# B6x register map
Vendor: XiaoMan; Series: B6 SOC; File version: 20260307
CPU: CM0+ r0p0, little endian, no MPU, no FPU, 2 interrupt priority bits
Registers are 32-bit, read-write, reset 0x0 unless marked. A register's access mark holds for its fields unless they carry their own. Offsets are from the block's base; [hi:lo] are bit positions; {n}, {i} and the like mark numbered series.

## SPIM — SPI Master
Base 0x40004000
0x00 RX_DATA
0x04 TX_DATA
0x08 TXRX_BGN
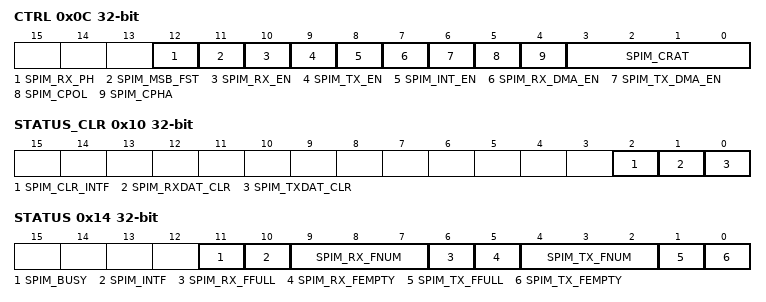
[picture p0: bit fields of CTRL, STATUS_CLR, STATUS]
0x0C CTRL
  [12] SPIM_RX_PH — 1: delay one phase to sample the miso
  [11] SPIM_MSB_FST — 1: MSB first, 0: LSB first
  [10] SPIM_RX_EN — receive from SPI slave enable
  [9] SPIM_TX_EN — transmit to SPI slave enable
  [8] SPIM_INT_EN — interrupt enable bit
  [7] SPIM_RX_DMA_EN — 0: RX work as mcu mode
  [6] SPIM_TX_DMA_EN — 0: TX work as mcu mode
  [5] SPIM_CPOL — clock polarity bit, 0: sck is low in idle status, 1: sck is high in idle status
  [4] SPIM_CPHA — clock phase bit, 0: sck sample data in first edge, 1: sck sample data in second edge
  [3:0] SPIM_CRAT — clock rate select,clk/2^(crat+1)
0x10 STATUS_CLR
  [2] SPIM_CLR_INTF — write 1 to clear intf status
  [1] SPIM_RXDAT_CLR — set 1 to clear spi RX fifo status and inner counter
  [0] SPIM_TXDAT_CLR — set 1 to clear spi TX fifo status and inner counter
0x14 STATUS
  [11] SPIM_BUSY — spim transfer busy signal
  [10] SPIM_INTF — rx or tx interrupt flag
  [9:7] SPIM_RX_FNUM — data number in rx fifo
  [6] SPIM_RX_FFULL — rx fifo full
  [5] SPIM_RX_FEMPTY — rx fifo empty
  [4:2] SPIM_TX_FNUM — data number in tx fifo
  [1] SPIM_TX_FFULL — tx fifo full
  [0] SPIM_TX_FEMPTY — tx fifo empty
0x18 DAT_LEN

## SPIS — SPI Slave
Base 0x40005000
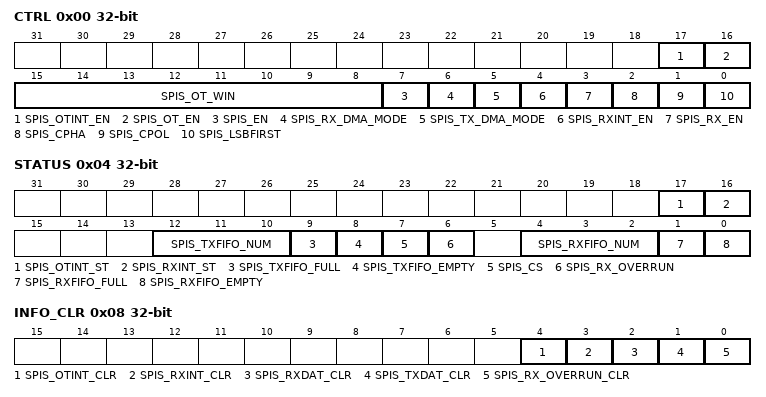
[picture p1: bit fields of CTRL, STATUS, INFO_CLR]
0x00 CTRL
  [17] SPIS_OTINT_EN — SPIS overtime interrupt enable
  [16] SPIS_OT_EN — SPIS overtime enable
  [15:8] SPIS_OT_WIN — config overtime window
  [7] SPIS_EN
  [6] SPIS_RX_DMA_MODE — 1: DMA mode, 0: MCU mode
  [5] SPIS_TX_DMA_MODE — 1: DMA mode, 0: MCU mode
  [4] SPIS_RXINT_EN
  [3] SPIS_RX_EN — spis rx control signal
  [2] SPIS_CPHA — 0: sample the data at the first clock edge, 1: sample the data at the second clock edge
  [1] SPIS_CPOL — 0: sample the data at the first clock edge, 1: sample the data at the second clock edge
  [0] SPIS_LSBFIRST — 0: MSB first, 1: LSB first
0x04 STATUS
  [17] SPIS_OTINT_ST — set as 1 when SPIS overtime event happen
  [16] SPIS_RXINT_ST — when SPIS RX 1 byte,spis_rxint is 1, cleared by spis_rxint_clr
  [12:10] SPIS_TXFIFO_NUM — the SPIS TX data number in txfifo
  [9] SPIS_TXFIFO_FULL — txfifo full
  [8] SPIS_TXFIFO_EMPTY — txfifo empty
  [7] SPIS_CS — 0: SPIS is selected, 1: SPIS is not selected
  [6] SPIS_RX_OVERRUN — SPIS rxfifo overrun error signal
  [4:2] SPIS_RXFIFO_NUM — the SPIS RX data number in rxfifo
  [1] SPIS_RXFIFO_FULL — rxfifo full
  [0] SPIS_RXFIFO_EMPTY — rxfifo empty
0x08 INFO_CLR
  [4] SPIS_OTINT_CLR — use clear spis_otint
  [3] SPIS_RXINT_CLR — use clear spis_rxint
  [2] SPIS_RXDAT_CLR — use to clear SPIS rxfifo point and data reg
  [1] SPIS_TXDAT_CLR — use to clear SPIS txfifo point and data reg
  [0] SPIS_RX_OVERRUN_CLR — use to clear spis_rx_overrun
0x0C TX_DAT
0x10 RX_DAT

## IWDT — Independent WatchDog Timer
Base 0x4002A000
0x00 LOAD — reload value register
0x04 VALUE — current value register
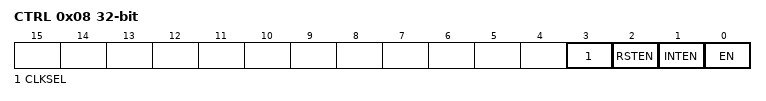
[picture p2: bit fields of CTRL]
0x08 CTRL
  [3] CLKSEL — 0:iwdt clk select apbclk, 1:iwdt clk select lsi
  [2] RSTEN — iwdg reset enable
  [1] INTEN — iwdg interrupt enable
  [0] EN — iwdg enable
0x0C INTCLR — interrupt flag clear register
0x10 RIS — interrupt flag register
0x100 LOCK — write 0x1ACCE551 to unlock

## APBMISC
Base 0x40031000
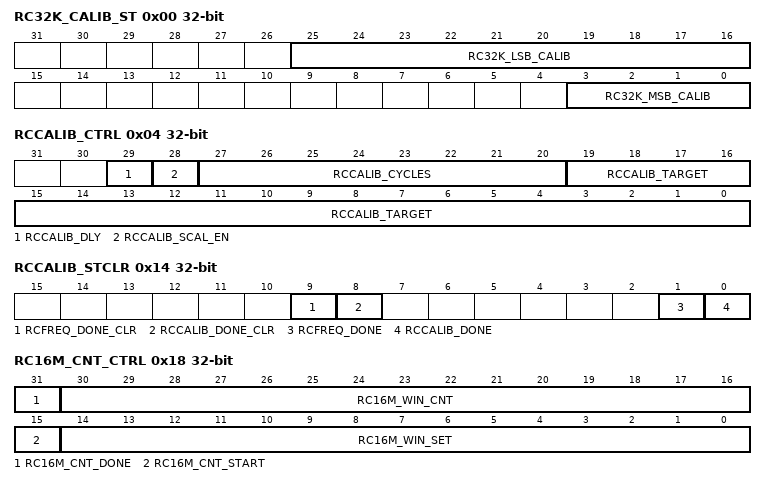
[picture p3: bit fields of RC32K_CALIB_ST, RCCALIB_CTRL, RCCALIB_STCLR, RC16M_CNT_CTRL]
0x00 RC32K_CALIB_ST
  [25:16] RC32K_LSB_CALIB
  [3:0] RC32K_MSB_CALIB — the final RC trim value
0x04 RCCALIB_CTRL
  [29] RCCALIB_DLY — when is 1: add one LSI clock delay between msb_calib or lsb_calib change to start count
  [28] RCCALIB_SCAL_EN — RCCALIB_SCAL_EN enable
  [27:20] RCCALIB_CYCLES — each RC calib step window is rccalib_cycles of LSI clock
  [19:0] RCCALIB_TARGET — rccalib_target = Fref * (rccalib_cycles+1) / Flsi
0x08 RCCALIB_START
0x0C RCFREQ_GET
0x10 RC_FREQ_VAL
0x14 RCCALIB_STCLR
  [9] RCFREQ_DONE_CLR, [8] RCCALIB_DONE_CLR, [1] RCFREQ_DONE, [0] RCCALIB_DONE
0x18 RC16M_CNT_CTRL
  [31] RC16M_CNT_DONE
  [30:16] RC16M_WIN_CNT
  [15] RC16M_CNT_START
  [14:0] RC16M_WIN_SET — RC16M cnt window
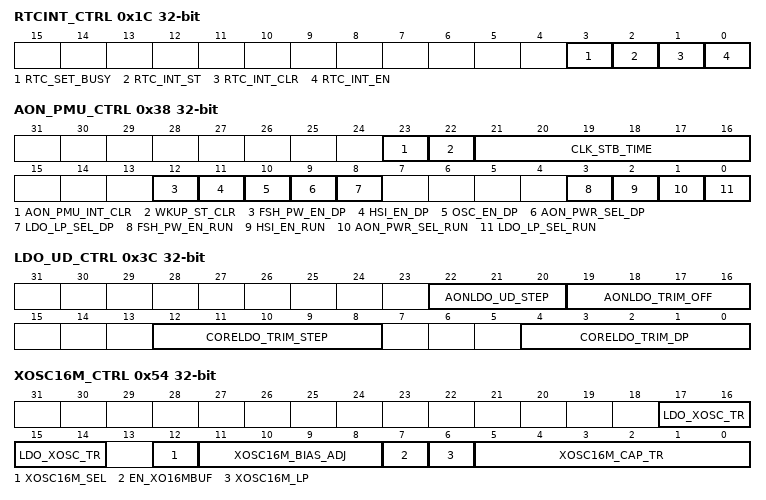
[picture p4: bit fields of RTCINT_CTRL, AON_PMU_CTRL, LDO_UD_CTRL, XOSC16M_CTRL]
0x1C RTCINT_CTRL
  [3] RTC_SET_BUSY
  [2] RTC_INT_ST — rtc interrupt status
  [1] RTC_INT_CLR — rtc intrrrupt clear
  [0] RTC_INT_EN — rtc interrupt enable
0x20 RTC_SEC
0x24 RTC_MS
0x28 RTC_ALARM_SEC
0x2C RTC_ALARM_MS
0x30 RTC_SEC_SHD
0x34 RTC_MS_SHD
0x38 AON_PMU_CTRL
  [23] AON_PMU_INT_CLR
  [22] WKUP_ST_CLR
  [21:16] CLK_STB_TIME — clock stable time for exit from deepsleep
  [12] FSH_PW_EN_DP
  [11] HSI_EN_DP
  [10] OSC_EN_DP
  [9] AON_PWR_SEL_DP
  [8] LDO_LP_SEL_DP
  [3] FSH_PW_EN_RUN
  [2] HSI_EN_RUN
  [1] AON_PWR_SEL_RUN
    0=AON_LDO (select AON_LDO out as AON power); 1=CORE_LDO (select CORE_LDO out as AON power)
  [0] LDO_LP_SEL_RUN
    1=HP LDO Mode (CORE LDO is lp mode); 0=LP LDO Mode (CORE LDO is HP mode)
0x3C LDO_UD_CTRL
  [22:20] AONLDO_UD_STEP, [19:16] AONLDO_TRIM_OFF, [12:8] CORELDO_TRIM_STEP, [4:0] CORELDO_TRIM_DP
0x40 PIOA_WKUP_POS
0x44 PIOA_WKUP_NEG
0x48 POWEROFF_WORD_CMD — written as 32'h77ED_29B4, chip go to POWEROFF
0x4C POWEROFF_LOG_CLR
0x50 RC16M_FREQ_TRIM
0x54 XOSC16M_CTRL
  [17:14] LDO_XOSC_TR, [12] XOSC16M_SEL, [11:8] XOSC16M_BIAS_ADJ, [7] EN_XO16MBUF, [6] XOSC16M_LP, [5:0] XOSC16M_CAP_TR
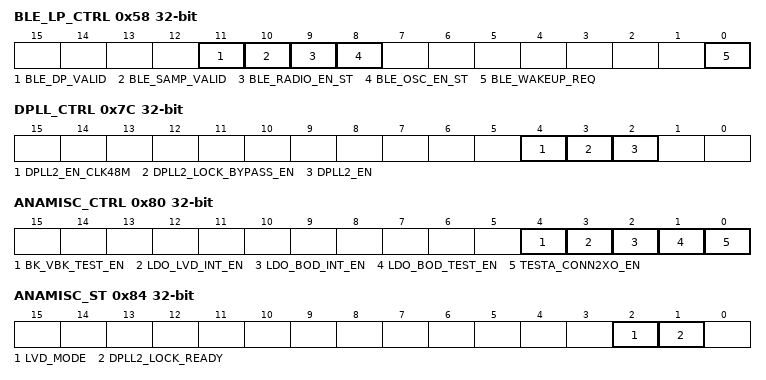
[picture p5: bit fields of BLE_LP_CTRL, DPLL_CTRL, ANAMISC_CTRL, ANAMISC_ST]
0x58 BLE_LP_CTRL
  [11] BLE_DP_VALID — when is 1, BB is deepsleep, and the remained sleep time is larger than auto cleared when BB exit deepsleep
  [10] BLE_SAMP_VALID — when is 1, ble_clkncnt_samp and ble_finecnt_samp can be read, auto cleared by HW
  [9] BLE_RADIO_EN_ST
  [8] BLE_OSC_EN_ST
  [0] BLE_WAKEUP_REQ — write 1, software wakeup the BB from BB in deepsleep
0x5C BLE_SYNC_TIME
0x60 BLE_FINECNT_BOUND
0x64 BLE_CLKNCNT_SAMP
0x68 BLE_FINECNT_SAMP
0x6C BLE_CLKNCNT_CFG
0x70 BLE_FINECNT_CFG
0x74 BLE_DP_TWCORE — the threhold for BB remained deepsleep time for Core go into Deepsleep
0x78 BLE_UPLOAD
0x7C DPLL_CTRL
  [4] DPLL2_EN_CLK48M, [3] DPLL2_LOCK_BYPASS_EN, [2] DPLL2_EN
0x80 ANAMISC_CTRL
  [4] BK_VBK_TEST_EN, [3] LDO_LVD_INT_EN, [2] LDO_BOD_INT_EN, [1] LDO_BOD_TEST_EN, [0] TESTA_CONN2XO_EN
0x84 ANAMISC_ST
  [2] LVD_MODE — 0: 1.8V IO voltage, 1: 3.3V IO valtage
  [1] DPLL2_LOCK_READY

## CACHE
Base 0x19000000
0x00 CCR
  [0] CACHE_EN — 0---cache disable, 1---cache enable
0x04 CCFR
  [3] CACHE_INST_DATA — 0---only instruction data can be cached, 1---both instruction and common data can be cached
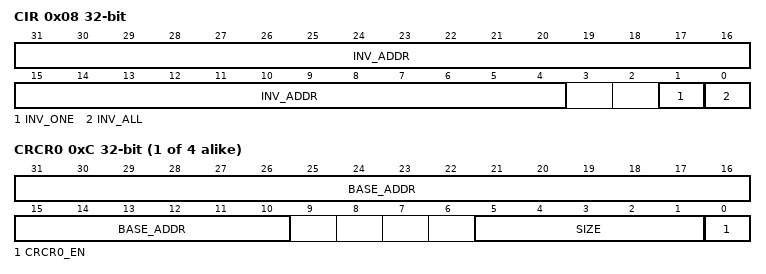
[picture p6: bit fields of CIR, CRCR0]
0x08 CIR
  [31:4] INV_ADDR — The high bits of cache line address of invalid one cache line operation.
  [1] INV_ONE — The control bit of invalid one cache line operation.
  [0] INV_ALL — The control bit of invalid all cache lines operation.
{0xC+4i} CRCR{i} (i=0..3)
  [31:10] BASE_ADDR — High 22 bits of base address of cacheable region.
  [5:1] SIZE — These control bits indicate the size of cacheable region.
  [0] CRCR{i}_EN — Cache region enable bit.

## DMACHCFG
Base 0x40027000
0x00 iflag0 — DMA interrupt status register 0.
0x04 iflag1 — DMA interrupt status register 1.
0x08 isfr0 — DMA interrupt status register 0.
0x0C isfr1 — DMA interrupt status register 1.
0x10 icfr0 — DMA interrupt status register 0.
0x14 icfr1 — DMA interrupt status register 1.
0x18 iefr0 — DMA interrupt status register 0.
0x1C iefr1 — DMA interrupt status register 1.
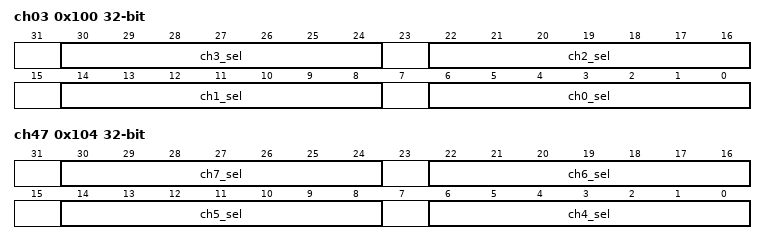
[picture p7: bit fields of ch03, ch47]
0x100 ch03 — DMA channel 0-3 multiplexing selection register.
  [30:24] ch3_sel — Swap TX/RX pins.
  [22:16] ch2_sel — Swap TX/RX pins.
  [14:8] ch1_sel — Baud rate register write enable.
  [6:0] ch0_sel — Data length selection.
0x104 ch47 — DMA channel 4-7 multiplexing selection register.
  [30:24] ch7_sel — Swap TX/RX pins.
  [22:16] ch6_sel — Swap TX/RX pins.
  [14:8] ch5_sel — Baud rate register write enable.
  [6:0] ch4_sel — Data length selection.

## BTMR — basic timer
Base 0x40020000
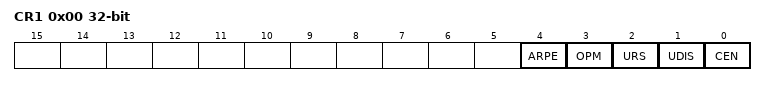
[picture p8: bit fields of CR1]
0x00 CR1
  [4] ARPE — auto reload preload enable
  [3] OPM — one plus mode
  [2] URS — update request source
  [1] UDIS — update disable
  [0] CEN — counter enable
0x04 CR2
  [6:4] MMS — master mode select
0x0C IER — interrupt enable register
0x10 IDR — interrupt disable register
0x14 IVS — interrupt vaild status register
0x18 RIF — interrupt raw flag register
0x1C IFM — interrupt masked flag register
0x20 ICR — interrupt clear status register
0x24 EGR — event generation register
0x34 CNT — timer counter
0x38 PSC — prescaler
0x3C ARR — auto-reload register
0x58 DMAEN — dma trigger event enable

## EXTI — External interrupt
Base 0x40028000
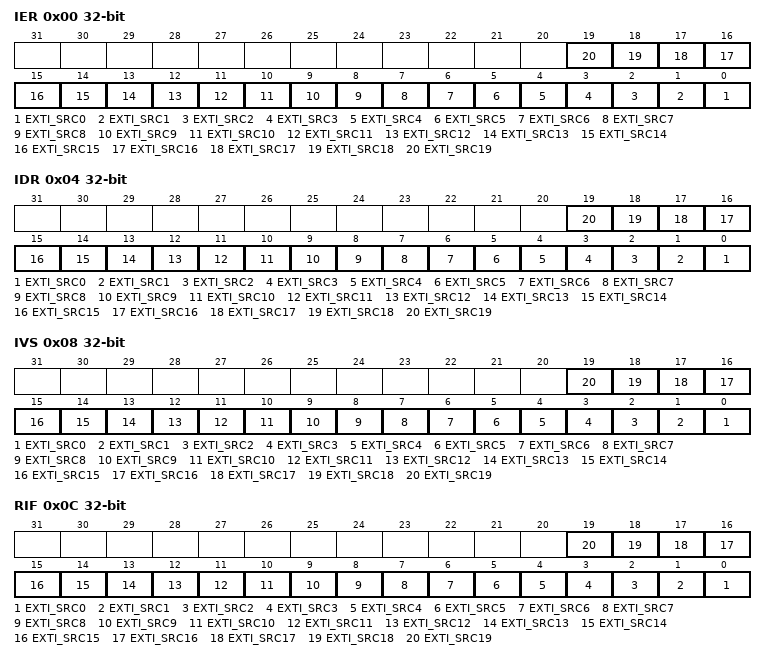
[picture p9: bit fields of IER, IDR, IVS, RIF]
0x00 IER — exti interrupt enable register
  [n] EXTI_SRC{n} (n=0..19) — EXTI IO{n:02}
0x04 IDR — exti interrupt disable register
  [n] EXTI_SRC{n} (n=0..19) — EXTI IO{n:02}
0x08 IVS — exti interrupt valid status register
  [n] EXTI_SRC{n} (n=0..19) — EXTI IO{n:02}
0x0C RIF — exti raw interrupt flag status register
  [n] EXTI_SRC{n} (n=0..19) — EXTI IO{n:02}
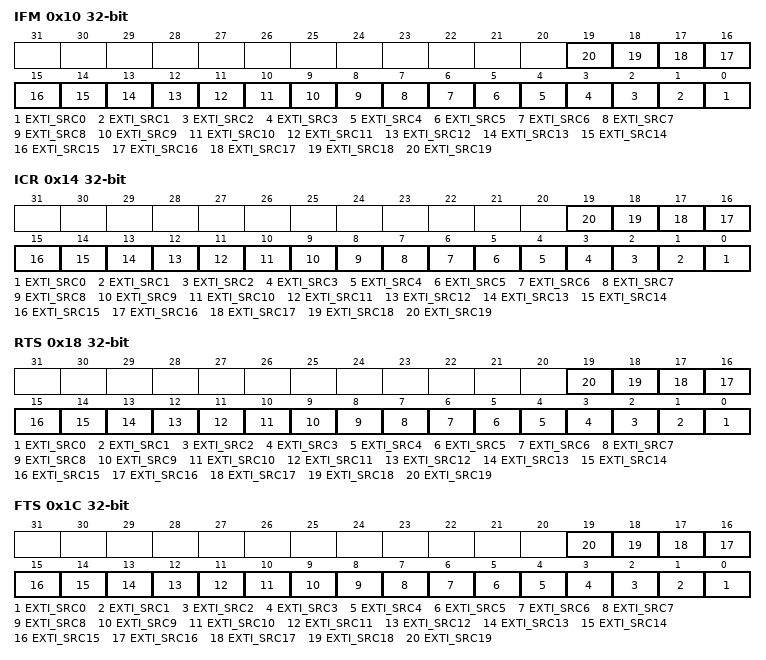
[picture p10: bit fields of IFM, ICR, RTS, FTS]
0x10 IFM — exti interrupt flag masked status register
  [n] EXTI_SRC{n} (n=0..19) — EXTI IO{n:02}
0x14 ICR — exti interrupt clear register
  [n] EXTI_SRC{n} (n=0..19) — EXTI IO{n:02}
0x18 RTS — exti rising edge trigger selection register
  [n] EXTI_SRC{n} (n=0..19) — EXTI IO{n:02}
0x1C FTS — exti falling edge trigger selection register
  [n] EXTI_SRC{n} (n=0..19) — EXTI IO{n:02}
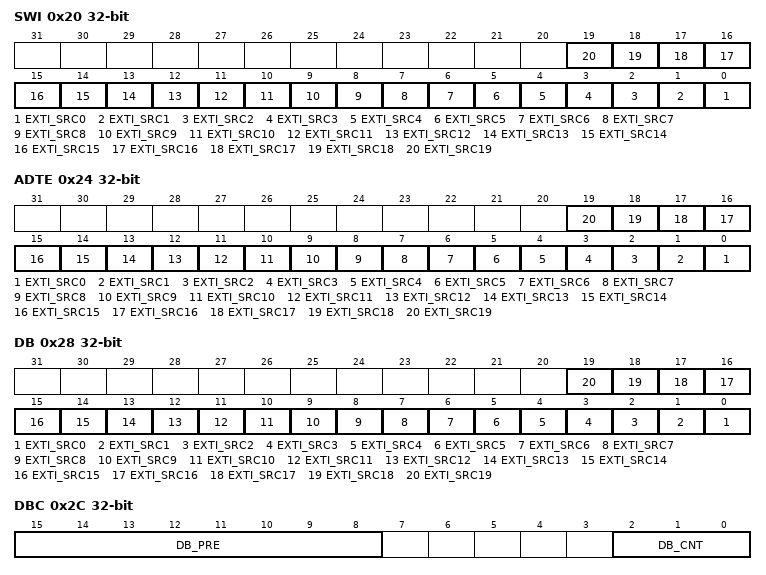
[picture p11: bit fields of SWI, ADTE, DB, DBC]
0x20 SWI — exti software interrupt event register
  [n] EXTI_SRC{n} (n=0..19) — EXTI IO{n:02}
0x24 ADTE — exti ad trigger enable
  [n] EXTI_SRC{n} (n=0..19) — EXTI IO{n:02}
0x28 DB — exti input debounce enable register
  [n] EXTI_SRC{n} (n=0..19) — EXTI IO{n:02}
0x2C DBC — exti input debounce sample rate control register
  [15:8] DB_PRE — debounce one cnt include current clk cycles, db_pre = db_pre_val + 1
  [2:0] DB_CNT — debounce cnts, db_cnt = db_cnt_val + 1
